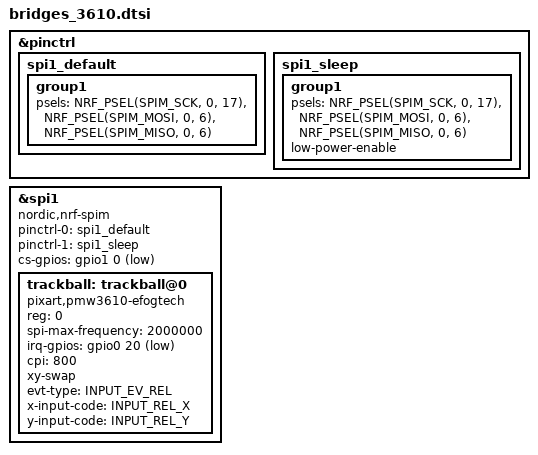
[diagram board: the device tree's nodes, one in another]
/*
 * Copyright (c) 2025 Vincent Franco
 * SPDX-License-Identifier: MIT
 */

#include <zephyr/dt-bindings/input/input-event-codes.h>

&pinctrl {
    spi1_default: spi1_default {
        group1 {
            psels = <NRF_PSEL(SPIM_SCK, 0, 17)>,
                    <NRF_PSEL(SPIM_MOSI, 0, 6)>,
                    <NRF_PSEL(SPIM_MISO, 0, 6)>;
        };
    };

    spi1_sleep: spi1_sleep {
        group1 {
            psels = <NRF_PSEL(SPIM_SCK, 0, 17)>,
                    <NRF_PSEL(SPIM_MOSI, 0, 6)>,
                    <NRF_PSEL(SPIM_MISO, 0, 6)>;
            low-power-enable;
        };
    };
};

&spi1 {
    status = "okay";
    compatible = "nordic,nrf-spim";
    pinctrl-0 = <&spi1_default>;
    pinctrl-1 = <&spi1_sleep>;
    pinctrl-names = "default", "sleep";
    cs-gpios = <&gpio1 0 GPIO_ACTIVE_LOW>;

    trackball: trackball@0 {
        status = "okay";
        compatible = "pixart,pmw3610-efogtech";
        reg = <0>;
        spi-max-frequency = <2000000>;
        irq-gpios = <&gpio0 20 (GPIO_ACTIVE_LOW | GPIO_PULL_UP)>;
        cpi = <800>;
        xy-swap;
        evt-type = <INPUT_EV_REL>;
        x-input-code = <INPUT_REL_X>;
        y-input-code = <INPUT_REL_Y>;
    };
};
